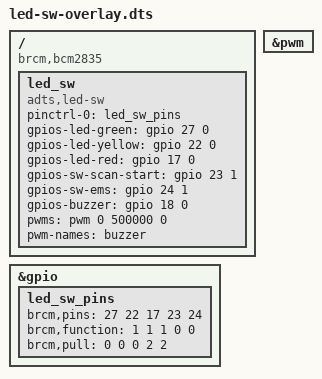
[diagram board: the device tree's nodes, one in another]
/*
 * led-sw-overlay.dts — /dev/led_sw (LED x3 + Switch x2 + Hardware PWM Buzzer) Device Tree Overlay
 *
 * RPi GPIO 핀 선언 (BCM 번호 / 40핀 헤더 물리 번호):
 *   - LED_초록        : BCM 27 / Pin 13
 *   - LED_노랑        : BCM 22 / Pin 15
 *   - LED_빨강        : BCM 17 / Pin 11
 *   - 수동 부저(Buzzer): BCM 18 / Pin 12 (Hardware PWM0)
 *   - 스위치_scan_start: BCM 23 / Pin 16 (Active Low, pull-up)
 *   - 스위치_ems       : BCM 24 / Pin 18 (Active Low, pull-up)
 *
 * ⚠️ 아래 brcm,pins 와 gpios-* 는 **BCM 번호**다. 물리 핀 번호를 쓰면 엉뚱한
 *   핀이 잡힌다. 드라이버(led_sw_driver.c)의 모듈 파라미터 기본값과 반드시
 *   같아야 한다 — 오버레이가 이기므로 어긋나면 드라이버 쪽이 조용히 무시된다.
 *
 * 빌드 및 적용:
 *   make dtbo
 *   sudo dtoverlay overlays/led-sw-overlay.dtbo
 */

/dts-v1/;
/plugin/;

/ {
	compatible = "brcm,bcm2835";

	fragment@0 {
		target = <&gpio>;
		__overlay__ {
			led_sw_pins: led_sw_pins {
				/* 27: Green, 22: Yellow, 17: Red, 23: Scan Start, 24: EMS (GPIO 18 is managed by hardware PWM) */
				brcm,pins = <27 22 17 23 24>;
				brcm,function = <1 1 1 0 0>; /* 1: Output, 0: Input */
				brcm,pull = <0 0 0 2 2>;     /* 0: None, 2: Pull-Up */
			};
		};
	};

	fragment@1 {
		target-path = "/";
		__overlay__ {
			led_sw {
				compatible = "adts,led-sw";
				status = "okay";

				pinctrl-names = "default";
				pinctrl-0 = <&led_sw_pins>;

				gpios-led-green      = <&gpio 27 0>;
				gpios-led-yellow     = <&gpio 22 0>;
				gpios-led-red        = <&gpio 17 0>;

				gpios-sw-scan-start  = <&gpio 23 1>;
				gpios-sw-ems         = <&gpio 24 1>;
				gpios-buzzer         = <&gpio 18 0>;
				pwms                 = <&pwm 0 500000 0>;
				pwm-names            = "buzzer";
			};
		};
	};

	fragment@2 {
		target = <&pwm>;
		__overlay__ {
			status = "okay";
		};
	};
};
